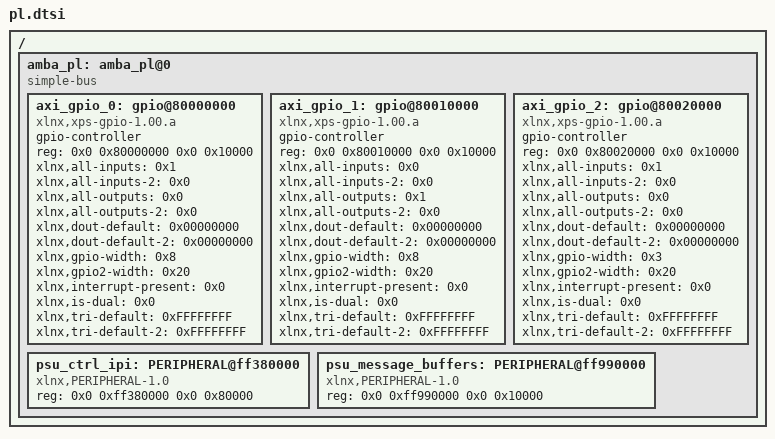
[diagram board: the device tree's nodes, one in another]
/*
 * CAUTION: This file is automatically generated by Xilinx.
 * Version:  
 * Today is: Wed Aug 29 14:33:25 2018
*/


/ {
	amba_pl: amba_pl@0 {
		#address-cells = <2>;
		#size-cells = <2>;
		compatible = "simple-bus";
		ranges ;
		axi_gpio_0: gpio@80000000 {
			#gpio-cells = <2>;
			compatible = "xlnx,xps-gpio-1.00.a";
			gpio-controller ;
			reg = <0x0 0x80000000 0x0 0x10000>;
			xlnx,all-inputs = <0x1>;
			xlnx,all-inputs-2 = <0x0>;
			xlnx,all-outputs = <0x0>;
			xlnx,all-outputs-2 = <0x0>;
			xlnx,dout-default = <0x00000000>;
			xlnx,dout-default-2 = <0x00000000>;
			xlnx,gpio-width = <0x8>;
			xlnx,gpio2-width = <0x20>;
			xlnx,interrupt-present = <0x0>;
			xlnx,is-dual = <0x0>;
			xlnx,tri-default = <0xFFFFFFFF>;
			xlnx,tri-default-2 = <0xFFFFFFFF>;
		};
		axi_gpio_1: gpio@80010000 {
			#gpio-cells = <2>;
			compatible = "xlnx,xps-gpio-1.00.a";
			gpio-controller ;
			reg = <0x0 0x80010000 0x0 0x10000>;
			xlnx,all-inputs = <0x0>;
			xlnx,all-inputs-2 = <0x0>;
			xlnx,all-outputs = <0x1>;
			xlnx,all-outputs-2 = <0x0>;
			xlnx,dout-default = <0x00000000>;
			xlnx,dout-default-2 = <0x00000000>;
			xlnx,gpio-width = <0x8>;
			xlnx,gpio2-width = <0x20>;
			xlnx,interrupt-present = <0x0>;
			xlnx,is-dual = <0x0>;
			xlnx,tri-default = <0xFFFFFFFF>;
			xlnx,tri-default-2 = <0xFFFFFFFF>;
		};
		axi_gpio_2: gpio@80020000 {
			#gpio-cells = <2>;
			compatible = "xlnx,xps-gpio-1.00.a";
			gpio-controller ;
			reg = <0x0 0x80020000 0x0 0x10000>;
			xlnx,all-inputs = <0x1>;
			xlnx,all-inputs-2 = <0x0>;
			xlnx,all-outputs = <0x0>;
			xlnx,all-outputs-2 = <0x0>;
			xlnx,dout-default = <0x00000000>;
			xlnx,dout-default-2 = <0x00000000>;
			xlnx,gpio-width = <0x3>;
			xlnx,gpio2-width = <0x20>;
			xlnx,interrupt-present = <0x0>;
			xlnx,is-dual = <0x0>;
			xlnx,tri-default = <0xFFFFFFFF>;
			xlnx,tri-default-2 = <0xFFFFFFFF>;
		};
		psu_ctrl_ipi: PERIPHERAL@ff380000 {
			compatible = "xlnx,PERIPHERAL-1.0";
			reg = <0x0 0xff380000 0x0 0x80000>;
		};
		psu_message_buffers: PERIPHERAL@ff990000 {
			compatible = "xlnx,PERIPHERAL-1.0";
			reg = <0x0 0xff990000 0x0 0x10000>;
		};
	};
};
